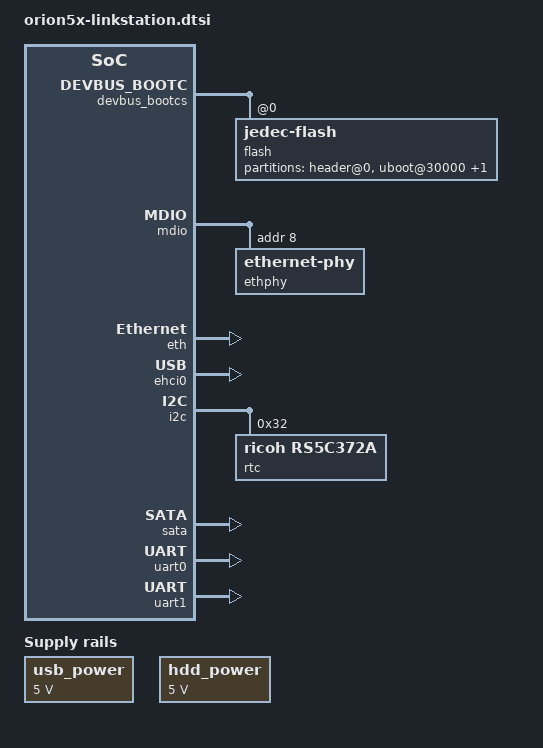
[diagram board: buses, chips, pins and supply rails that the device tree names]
#include "orion5x-mv88f5182.dtsi"
/ {
	chosen {
		bootargs = "console=ttyS0,115200n8 earlyprintk";
		stdout-path = &uart0;
	};
	soc {
		ranges = <MBUS_ID(0xf0, 0x01) 0 0xf1000000 0x100000>,
				 <MBUS_ID(0x09, 0x00) 0 0xf2200000 0x800>,
				 <MBUS_ID(0x01, 0x0f) 0 0xf4000000 0x40000>;
	};
	restart_poweroff {
		compatible = "restart-poweroff";
	};
	regulators {
		compatible = "simple-bus";
		#address-cells = <1>;
		#size-cells = <0>;
		pinctrl-0 = <&pmx_power_usb &pmx_power_hdd>;
		pinctrl-names = "default";
		usb_power: regulator@1 {
			compatible = "regulator-fixed";
			reg = <1>;
			regulator-name = "USB Power";
			regulator-min-microvolt = <5000000>;
			regulator-max-microvolt = <5000000>;
			enable-active-high;
			regulator-always-on;
			regulator-boot-on;
		};
		hdd_power: regulator@2 {
			compatible = "regulator-fixed";
			reg = <2>;
			regulator-name = "HDD Power";
			regulator-min-microvolt = <5000000>;
			regulator-max-microvolt = <5000000>;
			enable-active-high;
			regulator-always-on;
			regulator-boot-on;
		};
	};
};
&pinctrl {
	pmx_power_hdd: pmx-power-hdd {
		marvell,function = "gpio";
	};
	pmx_power_usb: pmx-power-usb {
		marvell,function = "gpio";
	};
};
&devbus_bootcs {
	status = "okay";
	devbus,keep-config;
	flash@0 {
		compatible = "jedec-flash";
		reg = <0 0x40000>;
		bank-width = <1>;
		partitions {
			compatible = "fixed-partitions";
			#address-cells = <1>;
			#size-cells = <1>;
			header@0 {
				reg = <0 0x30000>;
				read-only;
			};
			uboot@30000 {
				reg = <0x30000 0xF000>;
				read-only;
			};
			uboot_env@3F000 {
				reg = <0x3F000 0x1000>;
			};
		};
	};
};
&mdio {
	status = "okay";
	ethphy: ethernet-phy {
		reg = <8>;
	};
};
&eth {
	status = "okay";
	ethernet-port@0 {
		phy-handle = <&ethphy>;
	};
};
&ehci0 {
	status = "okay";
};
&i2c {
	status = "okay";
	rtc@32 {
		compatible = "ricoh,rs5c372a";
		reg = <0x32>;
	};
};
&wdt {
	status = "disabled";
};
&sata {
	status = "okay";
	nr-ports = <1>;
};
&uart0 {
	status = "okay";
};
&uart1 {
	status = "okay";
};
